# CH32F20xxx register map
Vendor: WCH Ltd.; File version: 1.1
Registers are 32-bit, read-write, reset 0x0 unless marked. A register's access mark holds for its fields unless they carry their own. Offsets are from the block's base; [hi:lo] are bit positions; {n}, {i} and the like mark numbered series.

## RCC — Reset and clock control
Base 0x40021000
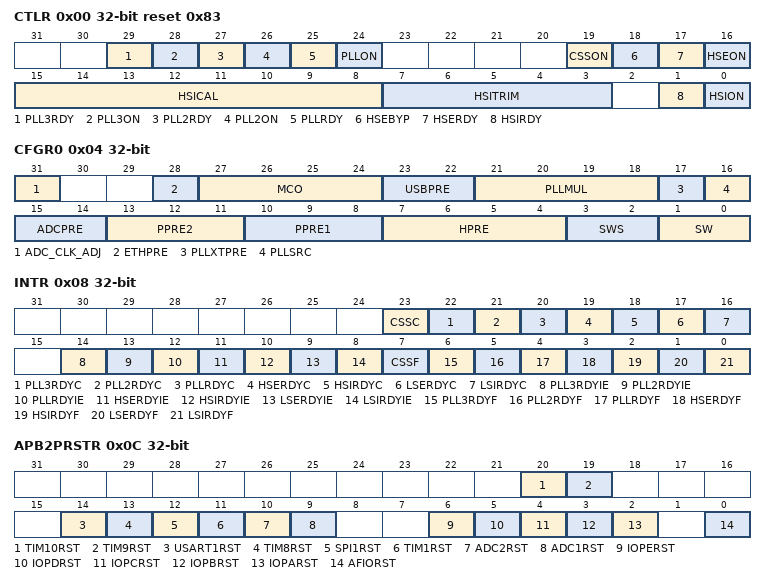
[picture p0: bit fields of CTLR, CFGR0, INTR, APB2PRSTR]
0x00 CTLR access per field reset 0x83 — Clock control register
  [29] PLL3RDY ro — PLL3 clock ready flag
  [28] PLL3ON rw — PLL3 enable
  [27] PLL2RDY ro — PLL2 clock ready flag
  [26] PLL2ON rw — PLL2 enable
  [25] PLLRDY ro — PLL clock ready flag
  [24] PLLON rw — PLL enable
  [19] CSSON rw — Clock Security System enable
  [18] HSEBYP rw — External High Speed clock Bypass
  [17] HSERDY ro — External High Speed clock ready flag
  [16] HSEON rw — External High Speed clock enable
  [15:8] HSICAL ro — Internal High Speed clock Calibration
  [7:3] HSITRIM rw — Internal High Speed clock trimming
  [1] HSIRDY ro — Internal High Speed clock ready flag
  [0] HSION rw — Internal High Speed clock enable
0x04 CFGR0 access per field — Clock configuration register (RCC_CFGR0)
  [31] ADC_CLK_ADJ rw — ADC clock ADJ
  [28] ETHPRE rw — ETH prescaler
  [27:24] MCO rw — Microcontroller clock output
  [23:22] USBPRE rw — USB prescaler
  [21:18] PLLMUL rw — PLL Multiplication Factor
  [17] PLLXTPRE rw — HSE divider for PLL entry
  [16] PLLSRC rw — PLL entry clock source
  [15:14] ADCPRE rw — ADC prescaler
  [13:11] PPRE2 rw — APB High speed prescaler (APB2)
  [10:8] PPRE1 rw — APB Low speed prescaler (APB1)
  [7:4] HPRE rw — AHB prescaler
  [3:2] SWS ro — System Clock Switch Status
  [1:0] SW rw — System clock Switch
0x08 INTR access per field — Clock interrupt register (RCC_INTR)
  [23] CSSC wo — Clock security system interrupt clear
  [22] PLL3RDYC wo — PLL3 Ready Interrupt Clear
  [21] PLL2RDYC wo — PLL2 Ready Interrupt Clear
  [20] PLLRDYC wo — PLL Ready Interrupt Clear
  [19] HSERDYC wo — HSE Ready Interrupt Clear
  [18] HSIRDYC wo — HSI Ready Interrupt Clear
  [17] LSERDYC wo — LSE Ready Interrupt Clear
  [16] LSIRDYC wo — LSI Ready Interrupt Clear
  [14] PLL3RDYIE rw — PLL3 Ready Interrupt Enable
  [13] PLL2RDYIE rw — PLL2 Ready Interrupt Enable
  [12] PLLRDYIE rw — PLL Ready Interrupt Enable
  [11] HSERDYIE rw — HSE Ready Interrupt Enable
  [10] HSIRDYIE rw — HSI Ready Interrupt Enable
  [9] LSERDYIE rw — LSE Ready Interrupt Enable
  [8] LSIRDYIE rw — LSI Ready Interrupt Enable
  [7] CSSF ro — Clock Security System Interrupt flag
  [6] PLL3RDYF ro — PLL3 Ready Interrupt flag
  [5] PLL2RDYF ro — PLL2 Ready Interrupt flag
  [4] PLLRDYF ro — PLL Ready Interrupt flag
  [3] HSERDYF ro — HSE Ready Interrupt flag
  [2] HSIRDYF ro — HSI Ready Interrupt flag
  [1] LSERDYF ro — LSE Ready Interrupt flag
  [0] LSIRDYF ro — LSI Ready Interrupt flag
0x0C APB2PRSTR — APB2 peripheral reset register (RCC_APB2PRSTR)
  [20] TIM10RST — TIM10 timer reset
  [19] TIM9RST — TIM9 timer reset
  [14] USART1RST — USART1 reset
  [13] TIM8RST — TIM8 timer reset
  [12] SPI1RST — SPI 1 reset
  [11] TIM1RST — TIM1 timer reset
  [10] ADC2RST — ADC 2 interface reset
  [9] ADC1RST — ADC 1 interface reset
  [6] IOPERST — IO port E reset
  [5] IOPDRST — IO port D reset
  [4] IOPCRST — IO port C reset
  [3] IOPBRST — IO port B reset
  [2] IOPARST — IO port A reset
  [0] AFIORST — Alternate function I/O reset
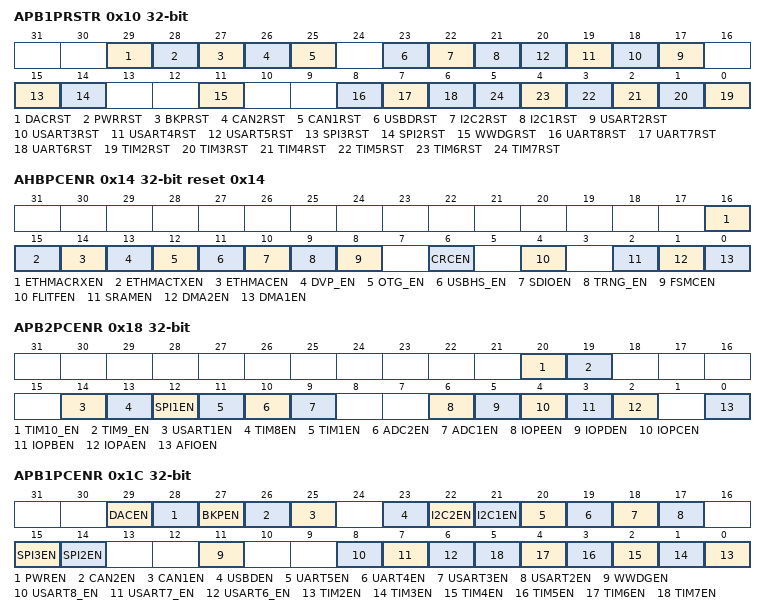
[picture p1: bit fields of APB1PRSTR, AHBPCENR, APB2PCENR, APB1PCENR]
0x10 APB1PRSTR — APB1 peripheral reset register (RCC_APB1PRSTR)
  [29] DACRST — DAC interface reset
  [28] PWRRST — Power interface reset
  [27] BKPRST — Backup interface reset
  [26] CAN2RST — CAN2 reset
  [25] CAN1RST — CAN1 reset
  [23] USBDRST — USBD reset
  [22] I2C2RST — I2C2 reset
  [21] I2C1RST — I2C1 reset
  [n+15] USART{n}RST (n=2..5) — USART {n} reset
  [15] SPI3RST — SPI3 reset
  [14] SPI2RST — SPI2 reset
  [11] WWDGRST — Window watchdog reset
  [8] UART8RST — UART 8 reset
  [7] UART7RST — UART 7 reset
  [6] UART6RST — UART 6 reset
  [n-2] TIM{n}RST (n=2..7) — Timer {n} reset
0x14 AHBPCENR reset 0x14 — AHB Peripheral Clock enable register (RCC_AHBPCENR)
  [16] ETHMACRXEN — Ethernet MAC RX clock enable
  [15] ETHMACTXEN — Ethernet MAC TX clock enable
  [14] ETHMACEN — Ethernet MAC clock enable
  [13] DVP_EN — DVP clock enable
  [12] OTG_EN — OTG clock enable
  [11] USBHS_EN — USBHS clock enable
  [10] SDIOEN — SDIO clock enable
  [9] TRNG_EN — TRNG clock enable
  [8] FSMCEN — FSMC clock enable
  [6] CRCEN — CRC clock enable
  [4] FLITFEN — FLITF clock enable
  [2] SRAMEN — SRAM interface clock enable
  [1] DMA2EN — DMA2 clock enable
  [0] DMA1EN — DMA clock enable
0x18 APB2PCENR — APB2 peripheral clock enable register (RCC_APB2PCENR)
  [20] TIM10_EN — TIM10 Timer clock enable
  [19] TIM9_EN — TIM9 Timer clock enable
  [14] USART1EN — USART1 clock enable
  [13] TIM8EN — TIM8 Timer clock enable
  [12] SPI1EN — SPI 1 clock enable
  [11] TIM1EN — TIM1 Timer clock enable
  [10] ADC2EN — ADC 2 interface clock enable
  [9] ADC1EN — ADC1 interface clock enable
  [6] IOPEEN — I/O port E clock enable
  [5] IOPDEN — I/O port D clock enable
  [4] IOPCEN — I/O port C clock enable
  [3] IOPBEN — I/O port B clock enable
  [2] IOPAEN — I/O port A clock enable
  [0] AFIOEN — Alternate function I/O clock enable
0x1C APB1PCENR — APB1 peripheral clock enable register (RCC_APB1PCENR)
  [29] DACEN — DAC interface clock enable
  [28] PWREN — Power interface clock enable
  [27] BKPEN — Backup interface clock enable
  [26] CAN2EN — CAN2 clock enable
  [25] CAN1EN — CAN1 clock enable
  [23] USBDEN — USBD clock enable
  [22] I2C2EN — I2C 2 clock enable
  [21] I2C1EN — I2C 1 clock enable
  [20] UART5EN — UART 5 clock enable
  [19] UART4EN — UART 4 clock enable
  [18] USART3EN — USART 3 clock enable
  [17] USART2EN — USART 2 clock enable
  [15] SPI3EN — SPI 3 clock enable
  [14] SPI2EN — SPI 2 clock enable
  [11] WWDGEN — Window watchdog clock enable
  [8] USART8_EN — USART 8 clock enable
  [7] USART7_EN — USART 7 clock enable
  [6] USART6_EN — USART 6 clock enable
  [n-2] TIM{n}EN (n=2..7) — Timer {n} clock enable
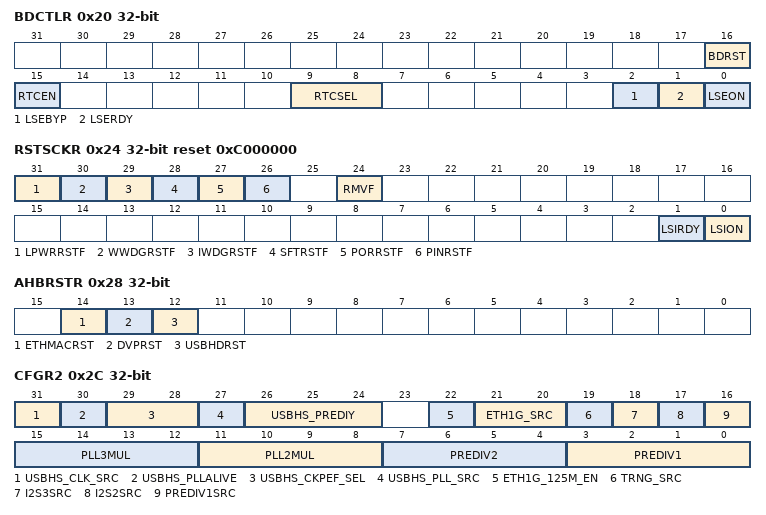
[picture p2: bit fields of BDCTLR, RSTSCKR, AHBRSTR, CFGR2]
0x20 BDCTLR access per field — Backup domain control register (RCC_BDCTLR)
  [16] BDRST rw — Backup domain software reset
  [15] RTCEN rw — RTC clock enable
  [9:8] RTCSEL rw — RTC clock source selection
  [2] LSEBYP rw — External Low Speed oscillator bypass
  [1] LSERDY ro — External Low Speed oscillator ready
  [0] LSEON rw — External Low Speed oscillator enable
0x24 RSTSCKR access per field reset 0xC000000 — Control/status register (RCC_RSTSCKR)
  [31] LPWRRSTF rw — Low-power reset flag
  [30] WWDGRSTF rw — Window watchdog reset flag
  [29] IWDGRSTF rw — Independent watchdog reset flag
  [28] SFTRSTF rw — Software reset flag
  [27] PORRSTF rw — POR/PDR reset flag
  [26] PINRSTF rw — PIN reset flag
  [24] RMVF rw — Remove reset flag
  [1] LSIRDY ro — Internal low speed oscillator ready
  [0] LSION rw — Internal low speed oscillator enable
0x28 AHBRSTR access per field — AHB reset register (RCC_APHBRSTR)
  [14] ETHMACRST rw — Ethernet MAC reset
  [13] DVPRST ro — DVP reset
  [12] USBHDRST rw — USBHD reset
0x2C CFGR2 — Clock configuration register2 (RCC_CFGR2)
  [31] USBHS_CLK_SRC — USB HS clock source
  [30] USBHS_PLLALIVE — USB HS Multiplication control
  [29:28] USBHS_CKPEF_SEL — USB HS Peference Clock source
  [27] USBHS_PLL_SRC — USB HS Multiplication Factor clock source
  [26:24] USBHS_PREDIY — USB HS PREDIV division factor
  [22] ETH1G_125M_EN — ETH1G _125M clock enable
  [21:20] ETH1G_SRC — ETH1G clock source
  [19] TRNG_SRC — TRNG clock source
  [18] I2S3SRC — I2S3 clock source
  [17] I2S2SRC — I2S2 clock source
  [16] PREDIV1SRC — PREDIV1 entry clock source
  [15:12] PLL3MUL — PLL3 Multiplication Factor
  [11:8] PLL2MUL — PLL2 Multiplication Factor
  [7:4] PREDIV2 — PREDIV2 division factor
  [3:0] PREDIV1 — PREDIV1 division factor
